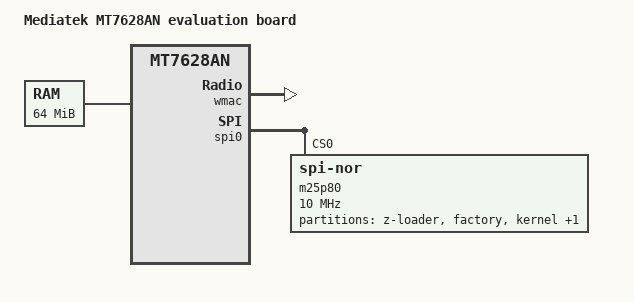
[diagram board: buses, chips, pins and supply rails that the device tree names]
/dts-v1/;

#include "mt7628an.dtsi"

/ {
	compatible = "mediatek,mt7628an-eval-board", "mediatek,mt7628an-soc";
	model = "Mediatek MT7628AN evaluation board";

	memory@0 {
		device_type = "memory";
		reg = <0x0 0x4000000>;
	};
};

&pinctrl {
	state_default: pinctrl0 {
		gpio {
			ralink,group = "i2c", "jtag";
			ralink,function = "gpio";
		};
	};
};

&wmac {
	status = "okay";
};

&spi0 {
	status = "okay";

	m25p80@0 {
		#address-cells = <1>;
		#size-cells = <1>;
		compatible = "jedec,spi-nor";
		reg = <0>;
		linux,modalias = "m25p80", "en25q64";
		spi-max-frequency = <10000000>;
		m25p,chunked-io = <32>;

		partition@0 {
			label = "z-loader";
			reg = <0x0 0x300000>;
			read-only;
		};

		/* dummy */
		factory: partition@1 {
			label = "factory";
			reg = <0x2f0000 0x10000>;
			read-only;
		};

		partition@2 {
			label = "kernel";
			reg = <0x300000 0x110000>;
			read-only;
		};

		partition@3 {
			label = "rootfs";
			reg = <0x410000 0x3f0000>;
		};
	};
};

/*
&wmac {
	status = "okay";
};
*/
